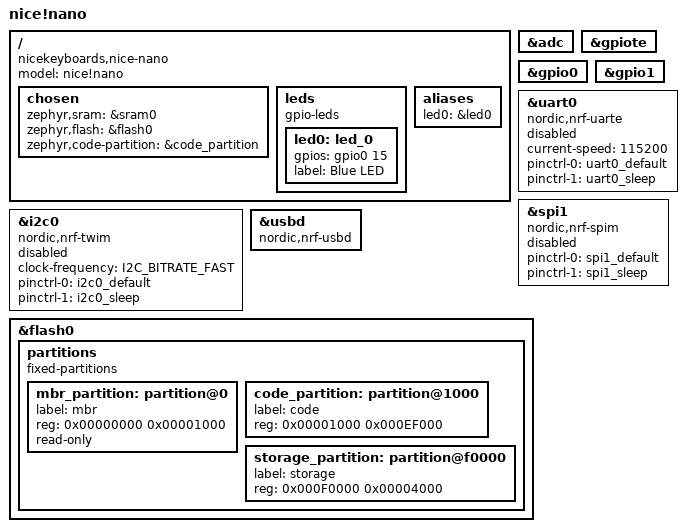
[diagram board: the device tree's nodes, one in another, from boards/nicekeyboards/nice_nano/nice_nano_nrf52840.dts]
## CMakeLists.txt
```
cmake_minimum_required(VERSION 3.20.0)

# Add this project root as a board root so boards/nicekeyboards/nice_nano/ is found
list(APPEND BOARD_ROOT ${CMAKE_CURRENT_SOURCE_DIR})

# Add this project root as a DTS root so the in-tree binding under
# dts/bindings/ (blled,ws2812-i2s-runtime) is found by the devicetree compiler.
list(APPEND DTS_ROOT ${CMAKE_CURRENT_SOURCE_DIR})

find_package(Zephyr REQUIRED HINTS $ENV{ZEPHYR_BASE})

project(bl_led VERSION 0.1.0)

target_include_directories(app PRIVATE include)

target_sources(app PRIVATE
    src/main.c
    src/led_effects.c
    src/led_animations.c
    src/ble_service.c
    src/battery.c
    # In-tree fork of the WS2812 I2S driver with a runtime-switchable colour
    # order (GRB / RGB / GRBW / RGBW). See drivers/ws2812_i2s_runtime/.
    drivers/ws2812_i2s_runtime/ws2812_i2s_runtime.c
)
```

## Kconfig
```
mainmenu "BL-LED Configuration"

source "Kconfig.zephyr"
```

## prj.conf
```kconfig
# ── Bluetooth ──────────────────────────────────────────────────────────────────
# Nordic UART Service (NUS) — see src/ble_service.c for the command protocol.
CONFIG_BT=y
CONFIG_BT_PERIPHERAL=y
CONFIG_BT_DEVICE_NAME="BL-LED"
CONFIG_BT_MAX_CONN=1
CONFIG_BT_NUS=y

# Use Zephyr's software link layer instead of Nordic's SoftDevice Controller.
#
# With the SDC, merely REFERENCING bt_enable() crashes this board at boot,
# before main() and before USB — reason 19, K_ERR_ARM_MEM_DATA_ACCESS. Note
# it is the reference, not the call: with --gc-sections, not calling
# bt_enable() lets the linker drop the whole stack INCLUDING its SYS_INIT
# entries, which is why "BT compiled in but not started" appeared to work.
#
# The SDC brings up MPSL at boot; the software controller does not, so this
# swaps out the entire suspect subsystem.
CONFIG_BT_CTLR=y
CONFIG_BT_LL_SW_SPLIT=y

# Nordic's CC310 crypto library fails to link against picolibc with this
# toolchain (undefined memmove / bad ARM-Thumb relocation). Nothing here needs
# it: no pairing, no encryption, no privacy — just an unauthenticated NUS
# link on a hobby LED controller.
CONFIG_HW_CC3XX=n
CONFIG_BT_CTLR_LE_ENC=n

# Entropy from the plain nRF RNG peripheral rather than CC310 — the CC3XX
# entropy driver needs nrfxlib headers that come with the crypto library
# disabled above.
CONFIG_ENTROPY_CC3XX=n
CONFIG_ENTROPY_NRF5_RNG=y

# NUS allocates its buffers from the system heap.
CONFIG_HEAP_MEM_POOL_SIZE=2048

# ── No USB, no console (headless production) ────────────────────────────────────
# The finished product runs sealed and headless — no terminal is ever attached.
# With USB CDC as the console, writing flash while no host drains the port hard-
# resets the board on EVERY settings save. An attached reader keeps the USB
# endpoint drained and masks it, which is why it looked like an intermittent
# regression: it only bit in the production configuration. Confirmed by A/B test
# (reset with no reader, never with `cat /dev/ttyACM0` running).
#
# USB is not needed at run time — UF2 flashing is handled by the bootloader,
# independent of the app — so bring up neither USB nor a console. Logging stays
# compiled (LOG_INF calls remain) but has no backend and goes nowhere; the
# onboard LED is the liveness/crash signal (see src/main.c). To get logs back
# for debugging, re-enable this block and call usb_enable() in main().
CONFIG_USB_DEVICE_STACK=n
CONFIG_SERIAL=n
CONFIG_CONSOLE=n
CONFIG_UART_CONSOLE=n

# ── GPIO (onboard LED, used as a liveness heartbeat) ──────────────────────────
CONFIG_GPIO=y

# ── Battery monitoring ─────────────────────────────────────────────────────────
# Cell voltage via SAADC through an external divider (see the overlay), exposed
# as the standard BLE Battery Service so any app reads it without a custom
# command.
#
# This is a GAUGE, not protection. It cannot disconnect the cell — nothing in
# the battery's current path is under firmware control — and it only runs while
# the firmware does. Use a hardware protection PCB for real over-discharge and
# short-circuit safety.
CONFIG_ADC=y
CONFIG_ADC_NRFX_SAADC=y
CONFIG_BT_BAS=y

# ── LED ring ───────────────────────────────────────────────────────────────────
# Driven over I2S, NOT SPI: every SPI transfer on this board — down to a single
# byte, on both SPIM1 and SPIM3, with the ring disconnected — crashes the CPU
# with K_ERR_ARM_MEM_DATA_ACCESS. That fault is unexplained; I2S avoids it.
CONFIG_LED_STRIP=y

# The strip is driven by the IN-TREE fork of the WS2812 I2S driver
# (drivers/ws2812_i2s_runtime/), which makes the colour order runtime-switchable
# (GRB / RGB / GRBW / RGBW) and persists it — one image drives both a 3-channel
# WS2812 strip and a 4-channel SK6812-RGBW strip. It is compiled directly as app
# source (see CMakeLists.txt) and binds the "blled,ws2812-i2s-runtime" node, so
# the upstream ws2812-i2s driver is left OFF.
CONFIG_WS2812_STRIP_I2S=n

# Must be explicit: the ws2812 node references the I2S controller by phandle
# rather than sitting on an i2s bus, so no driver auto-"selects" I2S and the
# device would never get instantiated.
CONFIG_I2S=y
CONFIG_I2S_NRFX=y

# ── Persistent settings (pixel count) ──────────────────────────────────────────
# Stored in NVS on the "storage" partition via the settings subsystem.
#
# NOTE: storage_partition in the board DTS was originally placed at 0xF4000,
# directly on top of the Adafruit UF2 bootloader. NVS erases every page it
# owns, so enabling this would have wiped the bootloader on the first save and
# left the board flashable only over SWD. The partition now ends at 0xF4000.
CONFIG_FLASH=y
CONFIG_FLASH_MAP=y
CONFIG_NVS=y
CONFIG_SETTINGS=y
CONFIG_SETTINGS_NVS=y

# Match the 16 KB partition exactly (4 x 4096-byte flash pages). The backend
# clamps this to whatever the partition holds, but the default of 8 would ask
# for 32 KB — twice the partition — so state it explicitly rather than relying
# on the clamp to keep NVS off the bootloader.
CONFIG_SETTINGS_NVS_SECTOR_COUNT=4

# Flash erase/write stalls the CPU and blocks the radio. This hands the timing
# to the BLE controller's ticker so a save cannot disrupt a connection event.
CONFIG_SOC_FLASH_NRF_RADIO_SYNC_TICKER=y

# ── Output format ──────────────────────────────────────────────────────────────
# Produces build/zephyr/zephyr.uf2 for drag-and-drop flashing onto the board.
CONFIG_BUILD_OUTPUT_UF2=y

# Use code_partition from DTS (starts at 0x1000, after the bootloader's MBR).
CONFIG_USE_DT_CODE_PARTITION=y

# ── Thread / stack sizes ───────────────────────────────────────────────────────
CONFIG_MAIN_STACK_SIZE=4096
CONFIG_SYSTEM_WORKQUEUE_STACK_SIZE=4096
CONFIG_BT_RX_STACK_SIZE=2048

# ── Logging ────────────────────────────────────────────────────────────────────
# Minimal mode routes log output straight to printk, synchronously.
CONFIG_LOG=y
CONFIG_LOG_MODE_MINIMAL=y

# NOTE: CONFIG_ARM_MPU=n was tried during bring-up and does NOT boot on this
# SoC. Leave the MPU at its default (enabled).

# ── Stack sizes: the root cause was a STACK OVERFLOW ─────────────────────────
#
# Both failures on this board — any SPI transfer, and bt_enable() — were the
# same bug. Proof came from toggling the MPU stack guard and watching the
# fault code change:
#
#   guards ON  -> K_ERR_ARM_MEM_DATA_ACCESS (19): the MPU trapped a write into
#                 the guard region, i.e. it caught the overflow cleanly.
#   guards OFF -> K_ERR_ARM_USAGE_ILLEGAL_EPSR (35): nothing caught it, the
#                 stack was corrupted, and a return jumped to garbage.
#
# That is a stack overflow, and HW_STACK_PROTECTION was reporting it correctly
# — it must stay ON. It is a diagnosis, not the disease.
#
# NOT main's stack: MAIN_STACK_SIZE=8192 was tried against the SPI fault and
# changed nothing. Both failing paths do their work in INTERRUPT context, and
# ISR_STACK_SIZE defaults to only 2048.
CONFIG_HW_STACK_PROTECTION=y
CONFIG_ISR_STACK_SIZE=4096
```

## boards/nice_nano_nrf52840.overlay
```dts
/*
 * Device Tree overlay for nice!nano — WS2812 driven over I2S.
 *
 * WHY I2S AND NOT SPI:
 * Every SPI transfer on this board faults with K_ERR_ARM_MEM_DATA_ACCESS (an
 * MPU data-access violation), including a bare 1-byte spi_write_dt(), on both
 * SPIM1 and SPIM3, with the strip disconnected. That crash is unexplained.
 * I2S drives the same pin through a separate path and works.
 *
 * Data goes out on P0.29.
 *
 * I2S requires SCK and LRCK to be assigned even though WS2812 uses only the
 * data line, so they are parked on P0.22 and P0.24 — free on this board and
 * nothing is wired to them. They toggle harmlessly.
 */

#include <zephyr/dt-bindings/led/led.h>
#include <zephyr/dt-bindings/adc/adc.h>
#include <zephyr/dt-bindings/adc/nrf-adc.h>

/ {
    chosen {
        /* No console: the app runs headless (see prj.conf). USB CDC as the
         * console resets the board on flash writes when no host drains the
         * port, so USB is not brought up at all. */

        /* The SoC dtsi points entropy at the CryptoCell. That driver is
         * disabled (CONFIG_HW_CC3XX=n — it fails to link against picolibc
         * with this toolchain), so use the plain RNG peripheral instead. */
        zephyr,entropy = &rng;
    };

    aliases {
        led-strip = &led_strip;
    };

    led_strip: ws2812 {
        /*
         * In-tree fork of the WS2812 I2S driver (drivers/ws2812_i2s_runtime/)
         * with a RUNTIME-switchable colour order, so one firmware image drives
         * both a 3-channel GRB WS2812 strip and a 4-channel GRBW SK6812-RGBW
         * strip. The order is set over BLE ("O<order>") and persisted to NVS.
         */
        compatible = "blled,ws2812-i2s-runtime";

        i2s-dev = <&i2s0>;
        /*
         * MAXIMUM supported pixels, not the number connected. This sizes the
         * static I2S DMA buffer, so it is fixed at build time; the count
         * actually lit is set over BLE ("N<count>") and persisted to NVS.
         *
         * 72 = two 36-pixel rings wired in series, the largest product build.
         * Cost is ~24 bytes of RAM per pixel of headroom.
         */
        chain-length = <72>;

        /*
         * DEFAULT colour order: GRB (a stock WS2812), used until the app sets
         * one from NVS at boot. The runtime may switch to RGB/GRBW/RGBW over
         * BLE; `max-colors` sizes the I2S DMA buffer for the widest of those (4,
         * for the RGBW variants) so widening the order at run time still fits.
         */
        color-mapping = <LED_COLOR_ID_GREEN
                         LED_COLOR_ID_RED
                         LED_COLOR_ID_BLUE>;
        max-colors = <4>;

        reset-delay = <120>;

        /*
         * Default 300 us is not enough — the peripheral is still draining
         * when the next write arrives and it gets rejected with -EIO
         * ("Cannot write in state: 3" = I2S_STATE_STOPPING).
         *
         * 10 ms is the value that produced the best result so far: the strip
         * showed red, then a single green pixel, i.e. more than one frame got
         * through. Not yet reliable for every frame.
         */
        extra-wait-time = <10000>;
    };
};

/*
 * Battery sense — INTERNAL VDDHDIV5, no external parts.
 *
 * The SAADC has a special input, VDDHDIV5, that samples the chip's VDDH pin
 * divided by 5 inside the die — no divider resistors, no GPIO consumed. On the
 * nice!nano the cell (B+) feeds VDDH, so this reads the battery directly; it is
 * how a genuine nice!nano v2 measures its own battery. The x5 is undone by the
 * vbatt full/output ratio below, so battery.c needs no change.
 *
 * A cell tops out at 4.2 V, over the SAADC's 3.6 V ceiling at the best gain, so
 * it must be scaled: 4.2 V / 5 = 0.84 V max at the input, comfortably inside the
 * 3.6 V full-scale window.
 *
 * CAVEATS:
 *   - This measures VDDH, not the cell as such. On USB power the rail is the
 *     ~5 V input, not the battery, so a reading of ~5 V means "on charger", not
 *     "overcharged cell". Trust the number only on battery.
 *   - Requires that B+ actually reaches VDDH — true on genuine nice!nano and
 *     most clones. VERIFY once against a multimeter on the cell before trusting
 *     it, the same way the resistor version below was validated.
 *
 * PREVIOUS external-divider version (P0.02/AIN0), kept for reference if the two
 * resistors are ever fitted:
 *
 *   BAT+ ──[ 100k ]──┬──[ 100k ]── GND
 *                    │
 *                  P0.02 (AIN0)
 *
 *   channel@0: zephyr,input-positive = <NRF_SAADC_AIN0>;
 *              acquisition-time = 40 us (50k source impedance needs a long
 *              window to charge the sampling cap);
 *   vbatt:     output-ohms = <100000>; full-ohms = <200000>;
 *
 * Some clones instead ship a divider on P0.31/AIN7 — if yours does, use AIN7
 * and MEASURE the ratio, it varies.
 */
&adc {
    status = "okay";
    #address-cells = <1>;
    #size-cells = <0>;

    channel@0 {
        reg = <0>;
        zephyr,gain = "ADC_GAIN_1_6";              /* 0.6 V ref x 6 = 3.6 V FS */
        zephyr,reference = "ADC_REF_INTERNAL";
        /* VDDHDIV5 is a low-impedance internal source, but a generous window
         * costs nothing here and keeps the reading quiet. */
        zephyr,acquisition-time = <ADC_ACQ_TIME(ADC_ACQ_TIME_MICROSECONDS, 40)>;
        zephyr,input-positive = <NRF_SAADC_VDDHDIV5>;
        zephyr,resolution = <12>;
    };
};

/ {
    /*
     * Battery sense scaling. The "voltage-divider" binding is reused purely for
     * its full/output ratio: battery.c multiplies the ADC reading by
     * full-ohms/output-ohms, so 5/1 undoes the VDDHDIV5 divide-by-five and
     * recovers the cell voltage. There are no physical resistors now.
     *
     * Kept enabled (status = "okay") because the sense path is always present:
     * VDDHDIV5 is internal and cannot be "unfitted" like the old resistors. The
     * plausibility window in battery.c still guards against a board where B+
     * does not reach VDDH — an implausible reading disables monitoring rather
     * than blanking the strip. VERIFY once against a multimeter on the cell.
     */
    vbatt: vbatt {
        compatible = "voltage-divider";
        status = "okay";
        io-channels = <&adc 0>;
        output-ohms = <1>;      /* VDDHDIV5 → cell = reading x 5 */
        full-ohms   = <5>;
    };
};

&pinctrl {
    i2s0_default_alt: i2s0_default_alt {
        group1 {
            psels = <NRF_PSEL(I2S_SCK_M, 0, 22)>,
                    <NRF_PSEL(I2S_LRCK_M, 0, 24)>,
                    <NRF_PSEL(I2S_SDOUT, 0, 29)>;
        };
    };
};

&i2s0 {
    status = "okay";
    pinctrl-0 = <&i2s0_default_alt>;
    pinctrl-names = "default";
};

/* SPI is not used for the strip — it crashes the CPU on this board. */
&spi1 {
    status = "disabled";
};

&spi3 {
    status = "disabled";
};
```

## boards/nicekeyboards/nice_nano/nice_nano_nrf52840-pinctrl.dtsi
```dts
/*
 * Copyright (c) nice!nano community
 * SPDX-License-Identifier: Apache-2.0
 *
 * nice!nano v2 pin-control definitions.
 * Adjust pin numbers to match your hardware revision if needed.
 */

&pinctrl {
	uart0_default: uart0_default {
		group1 {
			psels = <NRF_PSEL(UART_TX, 0, 6)>;
		};
		group2 {
			psels = <NRF_PSEL(UART_RX, 0, 8)>;
			bias-pull-up;
		};
	};

	uart0_sleep: uart0_sleep {
		group1 {
			psels = <NRF_PSEL(UART_TX, 0, 6)>,
			        <NRF_PSEL(UART_RX, 0, 8)>;
			low-power-enable;
		};
	};

	i2c0_default: i2c0_default {
		group1 {
			psels = <NRF_PSEL(TWIM_SDA, 0, 17)>,
			        <NRF_PSEL(TWIM_SCL, 0, 20)>;
		};
	};

	i2c0_sleep: i2c0_sleep {
		group1 {
			psels = <NRF_PSEL(TWIM_SDA, 0, 17)>,
			        <NRF_PSEL(TWIM_SCL, 0, 20)>;
			low-power-enable;
		};
	};

	spi1_default: spi1_default {
		group1 {
			psels = <NRF_PSEL(SPIM_SCK,  0, 22)>,
			        <NRF_PSEL(SPIM_MOSI, 0, 24)>,
			        <NRF_PSEL(SPIM_MISO, 1,  0)>;
		};
	};

	spi1_sleep: spi1_sleep {
		group1 {
			psels = <NRF_PSEL(SPIM_SCK,  0, 22)>,
			        <NRF_PSEL(SPIM_MOSI, 0, 24)>,
			        <NRF_PSEL(SPIM_MISO, 1,  0)>;
			low-power-enable;
		};
	};
};
```

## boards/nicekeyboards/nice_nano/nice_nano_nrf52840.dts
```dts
/*
 * Copyright (c) nice!nano community
 * SPDX-License-Identifier: Apache-2.0
 *
 * nice!nano v2 — nRF52840
 *
 * Pinout (Pro Micro compatible, top-left = pin 1):
 *   Left  (top→bottom): RAW, GND, RST, VCC, P0.22, P0.24, P1.00, P0.11, P1.04, P1.06
 *   Right (top→bottom): D+,  P0.06(TX), P0.08(RX), GND, P0.04, P0.02, P1.11, P1.13, P1.15, P0.29, P0.31, P0.30
 */

/dts-v1/;
#include <nordic/nrf52840_qiaa.dtsi>
#include "nice_nano_nrf52840-pinctrl.dtsi"

/ {
	model = "nice!nano";
	compatible = "nicekeyboards,nice-nano";

	chosen {
		zephyr,sram        = &sram0;
		zephyr,flash       = &flash0;
		zephyr,code-partition = &code_partition;
	};

	leds {
		compatible = "gpio-leds";
		led0: led_0 {
			gpios = <&gpio0 15 GPIO_ACTIVE_HIGH>;
			label = "Blue LED";
		};
	};

	aliases {
		led0 = &led0;
	};
};

&adc  { status = "okay"; };
&gpiote { status = "okay"; };
&gpio0  { status = "okay"; };
&gpio1  { status = "okay"; };

&uart0 {
	compatible = "nordic,nrf-uarte";
	status = "disabled";
	current-speed = <115200>;
	pinctrl-0 = <&uart0_default>;
	pinctrl-1 = <&uart0_sleep>;
	pinctrl-names = "default", "sleep";
};

&i2c0 {
	compatible = "nordic,nrf-twim";
	status = "disabled";
	clock-frequency = <I2C_BITRATE_FAST>;
	pinctrl-0 = <&i2c0_default>;
	pinctrl-1 = <&i2c0_sleep>;
	pinctrl-names = "default", "sleep";
};

&spi1 {
	compatible = "nordic,nrf-spim";
	status = "disabled";
	pinctrl-0 = <&spi1_default>;
	pinctrl-1 = <&spi1_sleep>;
	pinctrl-names = "default", "sleep";
};

/* spi3 is used by the WS2812 overlay — left unset here so the overlay owns it */

&usbd {
	compatible = "nordic,nrf-usbd";
	status = "okay";
};

&flash0 {
	partitions {
		compatible = "fixed-partitions";
		#address-cells = <1>;
		#size-cells = <1>;

		/* MBR — must not be overwritten (4 KB) */
		mbr_partition: partition@0 {
			label = "mbr";
			reg = <0x00000000 0x00001000>;
			read-only;
		};

		/*
		 * Application starts at 0x1000 — same as the original ZMK/Adafruit
		 * firmware. Zephyr's own BLE controller (BT_CTLR) replaces S140
		 * so no SoftDevice offset is needed.
		 *
		 * Ends at 0xF0000 to leave room for the storage partition below.
		 * The app is ~144 KB, so 956 KB of code space is not a constraint.
		 */
		code_partition: partition@1000 {
			label = "code";
			reg = <0x00001000 0x000EF000>;
		};

		/*
		 * NVS storage for the settings subsystem (16 KB = 4 flash pages).
		 *
		 * MUST end at or before 0xF4000: the Adafruit UF2 bootloader owns
		 * 0xF4000-0xFFFFF, and NVS erases every page it is given. This
		 * partition previously started AT 0xF4000 and was 0xC000 long,
		 * i.e. exactly on top of the bootloader — harmless only because
		 * nothing ever wrote to it. The first settings_save() would have
		 * erased the bootloader and left the board recoverable only over
		 * SWD. Do not move this back.
		 */
		storage_partition: partition@f0000 {
			label = "storage";
			reg = <0x000F0000 0x00004000>;
		};
	};
};
```

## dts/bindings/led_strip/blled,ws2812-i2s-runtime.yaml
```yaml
# Copyright (c) 2022 Jonathan Rico
# Copyright (c) 2026 bl-led
# SPDX-License-Identifier: Apache-2.0

description: |
  Worldsemi WS2812 / SK6812 LED strip over I2S, with a RUNTIME-SWITCHABLE
  colour order.

  A near-verbatim fork of "worldsemi,ws2812-i2s" (see drivers/ws2812_i2s_runtime/)
  that lets the on-wire byte order and channel COUNT be changed at run time via
  blled_ws2812_set_color_order() — so one firmware image drives both a 3-channel
  GRB WS2812 strip and a 4-channel GRBW SK6812-RGBW strip, selectable over BLE
  and persisted to flash.

  `color-mapping` gives the DEFAULT order used until the app sets one (GRB, like
  a stock WS2812). `max-colors` sizes the static I2S DMA buffer for the WIDEST
  order the runtime may select (4 for RGBW); it must be >= the length of
  `color-mapping` and any order later selected.

compatible: "blled,ws2812-i2s-runtime"

include: [base.yaml, ws2812.yaml]

properties:

  i2s-dev:
    type: phandle
    required: true
    description: Pointer to the I2S instance.

  max-colors:
    type: int
    default: 4
    description: |
      Maximum channels per pixel the runtime may select (3 for RGB/GRB, 4 for
      RGBW/GRBW). Sizes the static I2S DMA buffer; must be >= color-mapping
      length. Capped at 4 by the driver.

  out-active-low:
    type: boolean
    description: True if the output pin is active low.

  nibble-one:
    type: int
    default: 0x0E
    description: 4-bit value to shift out for a 1 pulse.

  nibble-zero:
    type: int
    default: 0x08
    description: 4-bit value to shift out for a 0 pulse.

  lrck-period:
    type: int
    default: 10
    description: LRCK (left/right clock) period in microseconds.

  extra-wait-time:
    type: int
    default: 300
    description: Extra microseconds to wait for the driver to flush its I2S queue.
```

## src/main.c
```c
/*
 * BL-LED — WS2812 ring controller, driven over BLE.
 *
 * Hardware notes that are easy to get wrong (see README.md):
 *   - The ring is driven over I2S, not SPI. SPI crashes this board.
 *   - Power the ring from an EXTERNAL supply with a shared ground. Powering
 *     it from RAW does not work: RAW reads ~4.24 V unloaded but collapses
 *     under load, and the ring stays dark.
 *   - Never drive data into an unpowered ring: it backfeeds through the
 *     WS2812 input protection diode and browns out the board. The bigger
 *     the ring, the more reliably it kills it.
 */

#include <errno.h>

#include <zephyr/kernel.h>
#include <zephyr/device.h>
#include <zephyr/drivers/gpio.h>
#include <zephyr/fatal.h>
#include <zephyr/logging/log.h>

#include <hal/nrf_gpio.h>

#include "battery.h"
#include "ble_service.h"
#include "led_effects.h"

LOG_MODULE_REGISTER(main, LOG_LEVEL_INF);

/*
 * Crash reporter on the onboard LED.
 *
 * A fatal error halts with interrupts disabled, and USB CDC needs interrupts
 * to transmit — so a crash dump can never reach the console on this board.
 * The LED is the only channel that survives. Pattern, repeating forever:
 *
 *   3 LONG blinks (600 ms) = "this is a crash report"
 *   then N SHORT blinks    = reason + 1:
 *       1 CPU exception  2 spurious IRQ  3 stack overflow
 *       4 kernel oops    5 kernel panic
 *      20 = reason 19 = K_ERR_ARM_MEM_DATA_ACCESS (MPU data-access fault)
 *
 * A SOLID (non-blinking) LED means it died before even this ran.
 */
#define FAULT_LED_PIN NRF_GPIO_PIN_MAP(0, 15)

void k_sys_fatal_error_handler(unsigned int reason, const z_arch_esf_t *esf)
{
    ARG_UNUSED(esf);

    nrf_gpio_cfg_output(FAULT_LED_PIN);

    while (1) {
        for (int i = 0; i < 3; i++) {
            nrf_gpio_pin_write(FAULT_LED_PIN, 1);
            k_busy_wait(600000);
            nrf_gpio_pin_write(FAULT_LED_PIN, 0);
            k_busy_wait(300000);
        }

        k_busy_wait(1200000);

        for (unsigned int i = 0; i <= reason; i++) {
            nrf_gpio_pin_write(FAULT_LED_PIN, 1);
            k_busy_wait(150000);
            nrf_gpio_pin_write(FAULT_LED_PIN, 0);
            k_busy_wait(350000);
        }

        k_busy_wait(2500000);
    }
}

#define LED0_NODE DT_ALIAS(led0)
static const struct gpio_dt_spec led0 = GPIO_DT_SPEC_GET(LED0_NODE, gpios);

/*
 * Slow heartbeat on the onboard LED.
 *
 * Kept from the bring-up work on purpose: USB serial on this board drops
 * output silently and goes quiet on re-enumeration, so its silence proves
 * nothing. A blinking LED is the one signal that reliably distinguishes
 * "running" from "crashed" without a terminal attached.
 */
static void heartbeat_fn(void *a, void *b, void *c)
{
    ARG_UNUSED(a); ARG_UNUSED(b); ARG_UNUSED(c);

    if (!device_is_ready(led0.port)) {
        return;
    }

    gpio_pin_configure_dt(&led0, GPIO_OUTPUT_INACTIVE);

    while (1) {
        gpio_pin_toggle_dt(&led0);
        k_sleep(K_MSEC(1000));
    }
}

K_THREAD_DEFINE(heartbeat_thread, 512, heartbeat_fn, NULL, NULL, NULL, 7, 0, 0);

int main(void)
{
    int err;

    /*
     * No USB, no console. The product ships headless — sealed case, battery,
     * power switch, no terminal ever attached — so the app brings up neither.
     *
     * This is not just tidiness: with USB CDC as the console, writing flash
     * while no host is draining the port hard-resets the board on EVERY
     * settings save. An attached terminal masks it (the host keeps the USB
     * endpoint drained), which is exactly why it looked like an intermittent
     * regression — it only bit when running the way production runs. USB is
     * not needed at run time; UF2 flashing is done by the bootloader,
     * independent of the app.
     *
     * Logs below are compiled but have no backend and go nowhere. The onboard
     * LED is the only liveness/crash signal — see the handlers above.
     */
    LOG_INF("BL-LED starting");

    err = led_effects_init();
    if (err) {
        LOG_ERR("LED strip init failed: %d", err);
    } else {
        /* Brightness and pixel count are restored from NVS by
         * led_effects_init() — deliberately not set here, or the saved
         * value would be overwritten on every boot. */
        led_effects_set_effect(EFFECT_RAINBOW);
        led_effects_start();
    }

    /* Battery gauge — see battery.h for what this does and does not protect
     * against. A failure here must not stop the lights working. */
    err = battery_init();
    if (err == -ENODEV) {
        /* Divider deliberately not fitted — a configuration, not a fault. */
        LOG_INF("Battery monitoring disabled");
    } else if (err) {
        LOG_ERR("Battery monitor failed to start: %d", err);
    } else {
        battery_start();
    }

    /*
     * Give USB time to enumerate before bringing up Bluetooth — but only in a
     * dev build that actually has USB. Removing this delay once coincided with
     * a board that would not boot (solid LED, no USB), so BLE coming up before
     * USB has settled is a suspect. Production has no USB (see prj.conf), so
     * this compiles out and BLE advertises immediately.
     */
    if (IS_ENABLED(CONFIG_USB_DEVICE_STACK)) {
        k_sleep(K_SECONDS(5));
    }

    err = ble_service_init();
    if (err) {
        LOG_ERR("BLE start failed: %d — LEDs will still run locally", err);
    }

    return 0;
}
```

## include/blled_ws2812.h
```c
#pragma once

#include <stdint.h>
#include <zephyr/device.h>

/*
 * Runtime colour-order control for the in-tree "blled,ws2812-i2s-runtime"
 * driver (drivers/ws2812_i2s_runtime/).
 *
 * The stock Zephyr ws2812-i2s driver freezes the on-wire byte order AND the
 * channel count at build time (its color_mapping is `static const` and the I2S
 * DMA buffer is sized from the mapping length). This fork moves the mapping and
 * count into mutable driver state so one firmware image can drive both a
 * 3-channel GRB WS2812 strip and a 4-channel GRBW SK6812-RGBW strip, chosen at
 * run time and persisted to flash by the app (see led_effects.c).
 *
 * Set the order the strip expects. `mapping` lists one LED_COLOR_ID_* per wire
 * byte, in on-wire order (e.g. {GREEN, RED, BLUE} for GRB, {GREEN, RED, BLUE,
 * WHITE} for GRBW). `num_colors` is how many entries `mapping` has; it must not
 * exceed the node's `max-colors` (which sized the DMA buffer). The White channel
 * is emitted as 0 — struct led_rgb carries no white — so RGBW strips show
 * correct R/G/B with the white die dark.
 *
 * Thread-safe: takes the driver's lock, so it is safe to call from a different
 * thread than the one driving the strip. Takes effect on the next frame.
 *
 * Returns 0 on success, -EINVAL if num_colors is 0 or above max-colors or a
 * mapping entry is not a RED/GREEN/BLUE/WHITE colour id, -ENODEV if dev is not
 * this driver.
 */
int blled_ws2812_set_color_order(const struct device *dev,
				 const uint8_t *mapping, uint8_t num_colors);
```

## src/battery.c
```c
#include "battery.h"
#include "led_effects.h"

#include <errno.h>

#include <zephyr/kernel.h>
#include <zephyr/devicetree.h>
#include <zephyr/drivers/adc.h>
#include <zephyr/logging/log.h>

#if defined(CONFIG_BT_BAS)
#include <zephyr/bluetooth/services/bas.h>
#endif

LOG_MODULE_REGISTER(battery, LOG_LEVEL_INF);

#define VBATT_NODE  DT_NODELABEL(vbatt)

#if !DT_NODE_HAS_STATUS(VBATT_NODE, okay)

/*
 * No divider fitted — see the vbatt node in the board overlay. Everything
 * compiles to stubs so main() needs no conditionals; battery_init() fails
 * with -ENODEV, which it already treats as non-fatal.
 */
int battery_init(void)
{
    LOG_INF("No battery divider fitted (vbatt disabled) — monitoring off");
    return -ENODEV;
}

void battery_start(void) { }
int battery_millivolts(void) { return -ENODATA; }
uint8_t battery_percent(void) { return 0; }
bool battery_is_critical(void) { return false; }

#else

static const struct adc_dt_spec adc_ch = ADC_DT_SPEC_GET(VBATT_NODE);

/* Divider maths: the ADC sees output_ohms/full_ohms of the cell voltage. */
#define DIVIDER_FULL_OHMS    DT_PROP(VBATT_NODE, full_ohms)
#define DIVIDER_OUTPUT_OHMS  DT_PROP(VBATT_NODE, output_ohms)

BUILD_ASSERT(DIVIDER_OUTPUT_OHMS > 0, "vbatt output-ohms must be non-zero");
BUILD_ASSERT(DIVIDER_FULL_OHMS >= DIVIDER_OUTPUT_OHMS,
             "vbatt full-ohms must be >= output-ohms");

/*
 * Thresholds, at the cell.
 *
 * These are deliberately well above the INR18650-35E's 2.5 V absolute floor.
 * Two reasons: readings are taken under load and sag several hundred mV below
 * the resting voltage, and the drain continues after cutoff (see battery.h),
 * so the margin is what keeps the cell off the floor until the switch is
 * thrown. Below ~2.5 V a Li-ion cell forms copper shunts and can ignite on
 * the NEXT charge, not at the time — hence the conservative numbers.
 */
#define BATT_CRITICAL_MV  3100   /* blank the LEDs */
#define BATT_LOW_MV       3400   /* warn only */

/*
 * Plausibility window. Outside this the reading is treated as a broken sense
 * circuit, NOT as a flat cell, and the lockout is not armed.
 *
 * Nothing below ~2.5 V can be a live cell that is currently powering the
 * board — the regulator would have dropped out first — so such a reading
 * means an unwired, floating or failed divider. Blanking the lights because
 * the measurement path broke would be the wrong failure mode: a sensor we
 * cannot trust must not be allowed to act.
 *
 * The upper bound catches the same fault in the other direction; no Li-ion
 * cell reaches 4.35 V.
 */
#define BATT_IMPLAUSIBLE_LO_MV  2500
#define BATT_IMPLAUSIBLE_HI_MV  4350

/*
 * Consecutive critical samples required before blanking. One noisy reading
 * should not kill the output, and at a 10 s interval this still reacts in
 * well under a minute.
 */
#define BATT_CRITICAL_STREAK  3

#define SAMPLE_INTERVAL   K_SECONDS(10)
#define SAMPLES_PER_READ  4      /* averaged, to damp LED switching noise */

/*
 * Li-ion discharge curve, descending. Linear interpolation between points.
 *
 * A straight 3.0-4.2 V linear map is badly wrong for Li-ion: the curve is
 * flat from ~90% to ~20%, so a linear gauge sits near 50% for most of the
 * runtime then collapses.
 */
struct batt_point {
    uint16_t mv;
    uint8_t  pct;
};

static const struct batt_point curve[] = {
    { 4200, 100 }, { 4100, 90 }, { 4000, 80 }, { 3950, 70 },
    { 3870, 60 },  { 3820, 50 }, { 3790, 40 }, { 3750, 30 },
    { 3700, 20 },  { 3600, 10 }, { 3400,  5 }, { 3000,  0 },
};

static int32_t  last_mv  = -1;
static uint8_t  last_pct;
static bool     critical;
static K_MUTEX_DEFINE(batt_mutex);

static uint8_t mv_to_percent(int32_t mv)
{
    if (mv >= curve[0].mv) {
        return 100;
    }

    for (size_t i = 1; i < ARRAY_SIZE(curve); i++) {
        if (mv >= curve[i].mv) {
            const struct batt_point *hi = &curve[i - 1];
            const struct batt_point *lo = &curve[i];
            int32_t span = hi->mv - lo->mv;
            int32_t into = mv - lo->mv;

            return lo->pct + (uint8_t)((into * (hi->pct - lo->pct)) / span);
        }
    }

    return 0;
}

static int sample_once(int32_t *out_mv)
{
    int16_t raw;
    struct adc_sequence seq = {
        .buffer      = &raw,
        .buffer_size = sizeof(raw),
    };

    int err = adc_sequence_init_dt(&adc_ch, &seq);
    if (err) {
        return err;
    }

    err = adc_read(adc_ch.dev, &seq);
    if (err) {
        return err;
    }

    int32_t mv = raw;

    err = adc_raw_to_millivolts_dt(&adc_ch, &mv);
    if (err) {
        return err;
    }

    /* Scale back up through the divider to the cell voltage. */
    *out_mv = (mv * DIVIDER_FULL_OHMS) / DIVIDER_OUTPUT_OHMS;
    return 0;
}

static void battery_thread_fn(void *a, void *b, void *c)
{
    ARG_UNUSED(a); ARG_UNUSED(b); ARG_UNUSED(c);

    int  critical_streak = 0;
    bool sense_fault     = false;

    while (1) {
        int32_t total = 0;
        int     good  = 0;

        for (int i = 0; i < SAMPLES_PER_READ; i++) {
            int32_t mv;

            if (sample_once(&mv) == 0) {
                total += mv;
                good++;
            }
            k_sleep(K_MSEC(5));
        }

        if (good == 0) {
            LOG_ERR("Battery sampling failed");
            k_sleep(SAMPLE_INTERVAL);
            continue;
        }

        int32_t mv = total / good;

        /* Sense circuit broken or not wired — report it and act on nothing. */
        if (mv < BATT_IMPLAUSIBLE_LO_MV || mv > BATT_IMPLAUSIBLE_HI_MV) {
            if (!sense_fault) {
                sense_fault = true;
                LOG_ERR("Battery sense implausible (%d mV) — divider missing "
                        "or broken. Monitoring disabled; LEDs unaffected.", mv);
            }
            critical_streak = 0;
            k_sleep(SAMPLE_INTERVAL);
            continue;
        }

        if (sense_fault) {
            sense_fault = false;
            LOG_INF("Battery sense recovered");
        }

        uint8_t pct = mv_to_percent(mv);

        k_mutex_lock(&batt_mutex, K_FOREVER);
        last_mv  = mv;
        last_pct = pct;
        bool already_critical = critical;
        k_mutex_unlock(&batt_mutex);

#if defined(CONFIG_BT_BAS)
        (void)bt_bas_set_battery_level(pct);
#endif

        if (mv <= BATT_CRITICAL_MV) {
            critical_streak++;
        } else {
            critical_streak = 0;
        }

        if (!already_critical && critical_streak >= BATT_CRITICAL_STREAK) {
            k_mutex_lock(&batt_mutex, K_FOREVER);
            critical = true;
            k_mutex_unlock(&batt_mutex);

            /*
             * Latched deliberately. Blanking the LEDs removes most of the
             * load, so the cell rebounds above the threshold within seconds;
             * an unlatched check would switch back on and oscillate.
             */
            LOG_ERR("Battery critical (%d mV) — blanking LEDs. "
                    "TURN THE POWER SWITCH OFF: this does not stop the drain.",
                    mv);
            led_effects_set_lockout(true);
        } else if (mv <= BATT_LOW_MV) {
            LOG_WRN("Battery low: %d mV (%u%%)", mv, pct);
        } else {
            LOG_INF("Battery: %d mV (%u%%)", mv, pct);
        }

        k_sleep(SAMPLE_INTERVAL);
    }
}

K_THREAD_DEFINE(battery_thread, 1024, battery_thread_fn, NULL, NULL, NULL,
                7, 0, K_TICKS_FOREVER);

int battery_init(void)
{
    if (!adc_is_ready_dt(&adc_ch)) {
        LOG_ERR("ADC channel not ready");
        return -ENODEV;
    }

    int err = adc_channel_setup_dt(&adc_ch);
    if (err) {
        LOG_ERR("ADC channel setup failed: %d", err);
        return err;
    }

    LOG_INF("Battery monitor ready (divider %u/%u)",
            DIVIDER_OUTPUT_OHMS, DIVIDER_FULL_OHMS);
    return 0;
}

void battery_start(void)
{
    k_thread_start(battery_thread);
}

int battery_millivolts(void)
{
    k_mutex_lock(&batt_mutex, K_FOREVER);
    int32_t mv = last_mv;
    k_mutex_unlock(&batt_mutex);

    return (mv < 0) ? -ENODATA : (int)mv;
}

uint8_t battery_percent(void)
{
    k_mutex_lock(&batt_mutex, K_FOREVER);
    uint8_t pct = last_pct;
    k_mutex_unlock(&batt_mutex);

    return pct;
}

bool battery_is_critical(void)
{
    k_mutex_lock(&batt_mutex, K_FOREVER);
    bool c = critical;
    k_mutex_unlock(&batt_mutex);

    return c;
}

#endif /* DT_NODE_HAS_STATUS(VBATT_NODE, okay) */
```

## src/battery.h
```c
#pragma once

#include <stdbool.h>
#include <stdint.h>

/*
 * Battery monitoring for a single Li-ion cell.
 *
 * SCOPE — read this before relying on it.
 *
 * This is a gauge and a convenience cutoff. It is NOT a protection circuit
 * and does not replace one:
 *
 *   - It only runs while the firmware runs. A crash, a hang, or a reflash
 *     leaves the cell entirely unguarded.
 *   - It cannot disconnect anything. Nothing in the battery's current path
 *     is under firmware control, so the "cutoff" only blanks the LEDs.
 *   - Blanking the LEDs does NOT stop the drain. A WS2812 draws ~1 mA even
 *     showing black, so a 72-pixel chain still pulls ~70 mA afterwards, plus
 *     whatever the SoC uses while advertising. The cell keeps discharging.
 *
 * The cutoff buys time and gives a visible warning. Only the hardware switch
 * actually removes the load.
 */

/* Set up the ADC channel. Returns 0, or a negative errno if the channel is
 * not ready. Monitoring does not start unless this succeeds. */
int battery_init(void);

/* Start the periodic sampling thread. */
void battery_start(void);

/* Last sampled cell voltage in millivolts, or -ENODATA before the first
 * valid sample. Readings outside a plausible cell range are treated as a
 * broken or unwired divider and discarded rather than acted on, so an
 * unpopulated sense circuit disables monitoring instead of blanking the
 * LEDs. */
int battery_millivolts(void);

/* Charge estimate 0-100 from the last sample, via a Li-ion discharge curve.
 * Readings taken under load sag, so this reads low while the LEDs are
 * bright — pessimistic, which is the safe direction. */
uint8_t battery_percent(void);

/* True once the critical threshold has been crossed. Latches: it does not
 * clear when the voltage recovers, because removing the LED load makes the
 * voltage jump back up and would otherwise oscillate. Cleared only by a
 * reboot. */
bool battery_is_critical(void);
```

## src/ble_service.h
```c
#pragma once

/**
 * Initialise Bluetooth and start advertising the NUS LED controller.
 * Returns 0 on success, negative errno on failure.
 */
int ble_service_init(void);
```

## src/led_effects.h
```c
#pragma once

#include <zephyr/kernel.h>
#include <stdint.h>

typedef enum {
    EFFECT_OFF       = 0,
    EFFECT_SOLID     = 1,
    EFFECT_RAINBOW   = 2,
    EFFECT_BREATHE   = 3,
    EFFECT_WORM      = 4,
    EFFECT_SPARKLE   = 5,   /* sparkle + travelling gradient; ring 1 diverges only in auto-colour */
    EFFECT_AURORA    = 6,   /* slow flowing gradient, tinted by the global colour */
    EFFECT_HEARTBEAT = 7,   /* lub-dub brightness pulse in the global colour      */
    EFFECT_FIREFLY   = 8,   /* sparse independent twinkles fading in and out      */
    EFFECT_PINWHEEL  = 9,   /* counter-rotating colour wedges                     */
    EFFECT_CONFETTI  = 10,  /* random self-coloured pops (ignores global colour)  */
} led_effect_t;

/* Keep in sync with the enum above: the highest valid effect index, used to
 * range-check the "E" command. */
#define EFFECT_MAX  EFFECT_CONFETTI

/*
 * Strip colour order — the on-wire byte order the physical LEDs expect. Chosen
 * at runtime ("O" command) and persisted, so one firmware image drives both a
 * 3-channel GRB WS2812 strip and a 4-channel GRBW SK6812-RGBW strip. The *W
 * variants add a White byte that is always emitted as 0 (the RGB pixel pipeline
 * has no white channel), so an RGBW strip shows correct R/G/B with the white
 * die dark. Applied to the strip driver via blled_ws2812_set_color_order().
 */
typedef enum {
    LED_ORDER_GRB  = 0,   /* WS2812 / plain SK6812 — 3 channels (default) */
    LED_ORDER_RGB  = 1,   /* RGB-ordered 3-channel strips                 */
    LED_ORDER_GRBW = 2,   /* SK6812-RGBW — 4 channels                     */
    LED_ORDER_RGBW = 3,   /* RGBW-ordered 4-channel strips                */
} led_color_order_t;

#define LED_ORDER_MAX  LED_ORDER_RGBW

/* Returns 0 on success, -ENODEV if the strip device is not ready.
 * The effect thread only starts if this returns 0. */
int led_effects_init(void);

/* Start the effect thread. Separate from init: the thread immediately drives
 * the whole strip, so the caller controls when that happens. */
void led_effects_start(void);

/*
 * Active pixel count — how many LEDs are physically connected.
 *
 * The DTS chain-length is the MAXIMUM the firmware supports; the active count
 * is set at runtime and persisted, so one image drives an 18, 36 or 72 pixel
 * chain. Data for pixels beyond the active count is still clocked out (the
 * driver always transmits a full frame) but simply falls off the end of a
 * shorter chain.
 */
int led_effects_pixel_count(void);      /* currently active count */
int led_effects_max_pixels(void);       /* DTS chain-length — the ceiling */

/* Set the active count and persist it. Takes effect on the next frame.
 * Returns -EINVAL if count is 0 or above the maximum. */
int led_effects_set_count(uint16_t count);

/* Drive a single solid color immediately, bypassing the effect thread.
 * For bring-up diagnostics. Returns the driver's update status. */
int led_effects_direct_fill(uint8_t r, uint8_t g, uint8_t b, uint8_t bri);

/* Clear the strip and light exactly one pixel. For bring-up diagnostics:
 * draws minimal current, so it separates "no data" from "brownout". */
int led_effects_direct_pixel(int idx, uint8_t r, uint8_t g, uint8_t b, uint8_t bri);
void led_effects_set_effect(led_effect_t effect);
led_effect_t led_effects_get_effect(void);

/* Current colour (the last "C" value). Reported by "?" so an app can sync its
 * UI on connect. Not persisted — cleared to the boot default on reset. */
void led_effects_set_color(uint8_t r, uint8_t g, uint8_t b);
void led_effects_get_color(uint8_t *r, uint8_t *g, uint8_t *b);

/* Brightness is persisted, like the pixel count, and restored at boot.
 * Do not set it unconditionally at startup — that would overwrite the
 * value the user saved. */
void led_effects_set_brightness(uint8_t brightness);
uint8_t led_effects_get_brightness(void);

/*
 * Animation speed, 0-255 (WLED-style): 0 slowest, 255 fastest, 128 the default.
 * It has no fixed meaning — each effect decides how to use it, typically via
 * led_speed_delay() in led_animations.h. Persisted and restored at boot, like
 * brightness. Non-animating effects (solid, off) ignore it.
 */
void led_effects_set_speed(uint8_t speed);
uint8_t led_effects_get_speed(void);

/*
 * Auto colour cycling: when enabled, the global colour is re-randomised at each
 * effect's cycle boundary (see led_cycle_color() in led_animations.h), so the
 * colour drifts on its own instead of staying at the last "C" value. Persisted
 * and restored at boot, like speed. Effects that ignore the colour (rainbow) or
 * have no cycle (solid, off) are unaffected while the mode is on.
 */
void led_effects_set_auto_color(bool on);
bool led_effects_get_auto_color(void);

/*
 * Pick a fresh random colour and make it the current one. Called by
 * led_cycle_color() from an effect at its cycle boundary; not normally called
 * directly. Thread-safe.
 */
void led_effects_cycle_color(void);

/*
 * Strip colour order. Persisted and restored at boot, like brightness. Setting
 * it re-programs the strip driver immediately (takes effect on the next frame)
 * and reschedules the deferred flash save. Returns -EINVAL for an unknown order.
 * The name helper returns a stable lowercase token ("grb"/"rgb"/"grbw"/"rgbw")
 * for the "?" report and the protocol; it never returns NULL.
 */
int led_effects_set_color_order(led_color_order_t order);
led_color_order_t led_effects_get_color_order(void);
const char *led_color_order_name(led_color_order_t order);

/* Force the strip black regardless of effect, for a critical battery.
 * Not persisted — a reboot clears it. */
void led_effects_set_lockout(bool lockout);
bool led_effects_is_locked_out(void);

/*
 * ── Ring geometry ────────────────────────────────────────────────────────────
 *
 * The active pixel count is split evenly into the active ring count (see
 * led_animations.h). How many rings is set at runtime and persisted, like the
 * pixel count; LED_MAX_RINGS is the compile-time ceiling. These report the
 * resulting layout and let it be calibrated to the physical mounting.
 */
int led_effects_ring_count(void);   /* rings mapped (1 if count is not divisible) */
int led_effects_ring_size(void);    /* pixels per ring                            */

/*
 * Active ring count — how many equal rings the strip is split into. Configured
 * at runtime and persisted, so one image drives a single- or multi-ring build.
 * The effective split (led_effects_ring_count) degrades to 1 if the pixel count
 * is not divisible into this many rings.
 */
int led_effects_get_rings(void);    /* configured ring count (the "R" value) */
int led_effects_max_rings(void);    /* LED_MAX_RINGS — the ceiling            */

/* Set the active ring count and persist it. Takes effect on the next frame.
 * Returns -EINVAL if rings is 0 or above LED_MAX_RINGS. */
int led_effects_set_rings(uint8_t rings);

/* Per-ring calibration readback (for the "?" report). top is a physical pixel
 * index; dir is +1 or -1. Returns -1 (top) / 0 (dir) for an invalid ring. */
int led_effects_ring_top(int ring);
int led_effects_ring_dir(int ring);

/*
 * Calibrate one ring: `top` is the physical pixel index sitting at the ring's
 * reference point, `dir` (+1/-1) its winding direction. Persisted. Returns
 * -EINVAL if the ring index is out of range, top is outside that ring, or dir
 * is not +/-1. Use led_effects_identify() to find the top pixel.
 */
int led_effects_set_ring_cal(int ring, int top, int dir);

/*
 * Diagnostic "identify" mode: light exactly one physical pixel (and blank the
 * rest) so a ring's top can be located. Overrides the running effect until a
 * new effect is selected; pass a negative index to turn it off. Not persisted.
 */
void led_effects_identify(int pixel);
```
